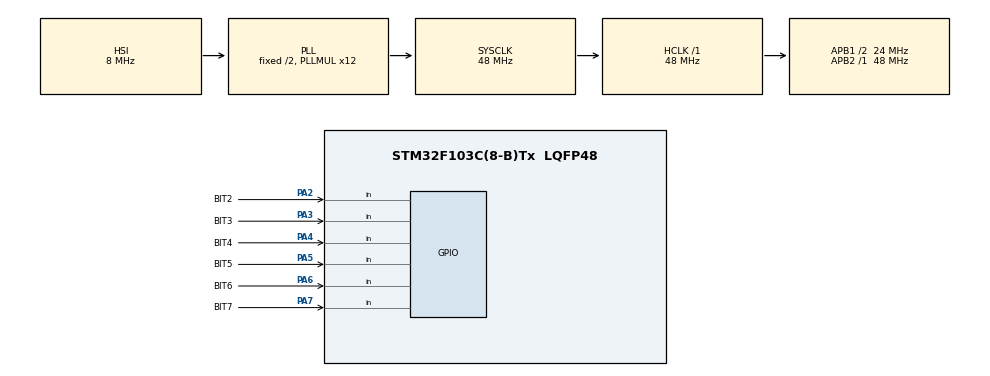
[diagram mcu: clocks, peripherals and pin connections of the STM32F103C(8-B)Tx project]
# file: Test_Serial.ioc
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Mcu.Family=STM32F1
Mcu.Name=STM32F103C(8-B)Tx
Mcu.Package=LQFP48
NVIC.PriorityGroup=NVIC_PRIORITYGROUP_4
PA13.Mode=Serial_Wire
PA13.Signal=SYS_JTMS-SWDIO
PA14.Mode=Serial_Wire
PA14.Signal=SYS_JTCK-SWCLK
PA2.GPIO_Label=BIT2
PA2.Signal=GPIO_Input
PA3.GPIO_Label=BIT3
PA3.Signal=GPIO_Input
PA4.GPIO_Label=BIT4
PA4.Signal=GPIO_Input
PA5.GPIO_Label=BIT5
PA5.Signal=GPIO_Input
PA6.GPIO_Label=BIT6
PA6.Signal=GPIO_Input
PA7.GPIO_Label=BIT7
PA7.Signal=GPIO_Input
PD0-OSC_IN.Mode=HSE-External-Oscillator
PD0-OSC_IN.Signal=RCC_OSC_IN
PD1-OSC_OUT.Mode=HSE-External-Oscillator
PD1-OSC_OUT.Signal=RCC_OSC_OUT
ProjectManager.HeapSize=0x200
ProjectManager.StackSize=0x400
ProjectManager.TargetToolchain=STM32CubeIDE
RCC.AHBFreq_Value=48000000
RCC.APB1CLKDivider=RCC_HCLK_DIV2
RCC.APB1Freq_Value=24000000
RCC.APB1TimFreq_Value=48000000
RCC.APB2Freq_Value=48000000
RCC.APB2TimFreq_Value=48000000
RCC.HCLKFreq_Value=48000000
RCC.HSEDivPLL=RCC_HSE_PREDIV_DIV2
RCC.PLLMUL=RCC_PLL_MUL12
RCC.SYSCLKFreq_VALUE=48000000
RCC.SYSCLKSource=RCC_SYSCLKSOURCE_PLLCLK
RCC.USBFreq_Value=48000000
board=custom

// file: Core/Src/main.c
/* USER CODE BEGIN Header */
/**
  ******************************************************************************
  * @file           : main.c
  * @brief          : Main program body
  ******************************************************************************
  * @attention
  *
  * Copyright (c) 2024 STMicroelectronics.
  * All rights reserved.
  *
  * This software is licensed under terms that can be found in the LICENSE file
  * in the root directory of this software component.
  * If no LICENSE file comes with this software, it is provided AS-IS.
  *
  ******************************************************************************
  */
/* USER CODE END Header */
#include "main.h"

void SystemClock_Config(void);
static void MX_GPIO_Init(void);
/* USER CODE BEGIN PFP */
uint8_t readBinaryInput(void);
/* USER CODE END PFP */

/* USER CODE BEGIN 0 */
uint8_t binaryValue;
/* USER CODE END 0 */

int main(void)
{

  /* MCU Configuration--------------------------------------------------------*/

  /* Reset of all peripherals, Initializes the Flash interface and the Systick. */
  HAL_Init();

  /* Configure the system clock */
  SystemClock_Config();

  /* Initialize all configured peripherals */
  MX_GPIO_Init();

  /* Infinite loop */
  while (1)
  {

    /* USER CODE BEGIN 3 */
    binaryValue = readBinaryInput();
  }
  /* USER CODE END 3 */
}

void SystemClock_Config(void)
{
  RCC_OscInitTypeDef RCC_OscInitStruct = {0};
  RCC_ClkInitTypeDef RCC_ClkInitStruct = {0};

  /** Initializes the RCC Oscillators according to the specified parameters
  * in the RCC_OscInitTypeDef structure.
  */
  RCC_OscInitStruct.OscillatorType = RCC_OSCILLATORTYPE_HSI;
  RCC_OscInitStruct.HSIState = RCC_HSI_ON;
  RCC_OscInitStruct.HSICalibrationValue = RCC_HSICALIBRATION_DEFAULT;
  RCC_OscInitStruct.PLL.PLLState = RCC_PLL_ON;
  RCC_OscInitStruct.PLL.PLLSource = RCC_PLLSOURCE_HSI_DIV2;
  RCC_OscInitStruct.PLL.PLLMUL = RCC_PLL_MUL12;
  if (HAL_RCC_OscConfig(&RCC_OscInitStruct) != HAL_OK)
  {
    Error_Handler();
  }

  /** Initializes the CPU, AHB and APB buses clocks
  */
  RCC_ClkInitStruct.ClockType = RCC_CLOCKTYPE_HCLK|RCC_CLOCKTYPE_SYSCLK
                              |RCC_CLOCKTYPE_PCLK1|RCC_CLOCKTYPE_PCLK2;
  RCC_ClkInitStruct.SYSCLKSource = RCC_SYSCLKSOURCE_PLLCLK;
  RCC_ClkInitStruct.AHBCLKDivider = RCC_SYSCLK_DIV1;
  RCC_ClkInitStruct.APB1CLKDivider = RCC_HCLK_DIV2;
  RCC_ClkInitStruct.APB2CLKDivider = RCC_HCLK_DIV1;

  if (HAL_RCC_ClockConfig(&RCC_ClkInitStruct, FLASH_LATENCY_1) != HAL_OK)
  {
    Error_Handler();
  }
}

static void MX_GPIO_Init(void)
{
  GPIO_InitTypeDef GPIO_InitStruct = {0};

  /* GPIO Ports Clock Enable */
  __HAL_RCC_GPIOD_CLK_ENABLE();
  __HAL_RCC_GPIOA_CLK_ENABLE();

  /*Configure GPIO pins : BIT2_Pin BIT3_Pin BIT4_Pin BIT5_Pin
                           BIT6_Pin BIT7_Pin */
  GPIO_InitStruct.Pin = BIT2_Pin|BIT3_Pin|BIT4_Pin|BIT5_Pin
                          |BIT6_Pin|BIT7_Pin;
  GPIO_InitStruct.Mode = GPIO_MODE_INPUT;
  GPIO_InitStruct.Pull = GPIO_NOPULL;
  HAL_GPIO_Init(GPIOA, &GPIO_InitStruct);

}

/* USER CODE BEGIN 4 */
uint8_t readBinaryInput(void) {
    uint8_t binaryValue = 0;

    // Read the state of each GPIO pin and update the binary value
    binaryValue |= (HAL_GPIO_ReadPin(BIT2_GPIO_Port, BIT2_Pin) << 0);
    binaryValue |= (HAL_GPIO_ReadPin(BIT3_GPIO_Port, BIT3_Pin) << 1);
    binaryValue |= (HAL_GPIO_ReadPin(BIT4_GPIO_Port, BIT4_Pin) << 2);
    binaryValue |= (HAL_GPIO_ReadPin(BIT5_GPIO_Port, BIT5_Pin) << 3);
    binaryValue |= (HAL_GPIO_ReadPin(BIT6_GPIO_Port, BIT6_Pin) << 4);
    binaryValue |= (HAL_GPIO_ReadPin(BIT7_GPIO_Port, BIT7_Pin) << 5);

    return binaryValue;
}
/* USER CODE END 4 */

void Error_Handler(void)
{
  __disable_irq();
  while (1)
  {
  }
}
